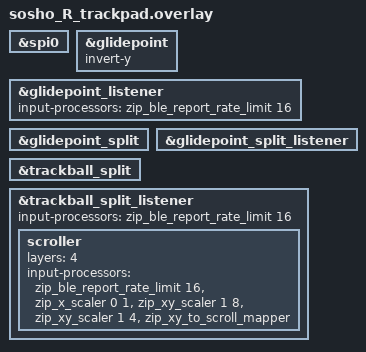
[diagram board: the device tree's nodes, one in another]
#include "sosho_R.dtsi"
#include <input/processors/report_rate_limit.dtsi>

/*
glidepoint_listnerは右手のトラックパッド
glidepoint_split_listenerとtrackball_split_listenerは
左手のトラックパッドとトラックボールの受けです。
ここにinput-processorというオプションをつけると、いろんな動きができます。
代表的なものを書いておきます。

・ポインタの移動を早くしたいとき
&zip_xy_scalerを使います。
分子 分母の順に数字を指定します。2 1なら2倍です。
input-processors = <&zip_xy_scaler 2 1>;

・スクロールを割り当てたいとき
zip_xy_to_scroll_mapperを使います。
ポインティングデバイスの動きをスクロールに変換してくれます。
input-processors = <&zip_xy_to_scroll_mapper>;

このオプションは複数併記することもできます。
input-processors = <&zip_xy_scaler 1 3>,<&zip_xy_to_scroll_mapper>;

詳しい情報はzmkのドキュメントを確認してください。
https://zmk.dev/docs/keymaps/input-processors
*/

&spi0 { status = "okay"; };
&glidepoint {
    status = "okay";
    invert-y;
};
&glidepoint_listener {
    status = "okay";
	/*
	Bluetooth のときだけ、PC へのレポートを 16 ms に 1 回までにまとめる（間引いた分の動きは次のレポートに足す）。
	作る速さが送る速さを上回ると、送りきれないレポートが溜まって遅れが積み上がり、キーまで遅れるため。
	USB では制限しない。数字を小さくすると滑らかになるが、溜まりやすくなる
	*/
	input-processors = <&zip_ble_report_rate_limit 16>;
	//input-processors = <&zip_ble_report_rate_limit 16>, <&zip_xy_scaler 2 1>;
};

&glidepoint_split { status = "okay"; };
&glidepoint_split_listener {
    status = "okay";
};

&trackball_split { status = "okay"; };
&trackball_split_listener {
	status = "okay";
	// レポートの間引きは glidepoint_listener と同じ（L4 のあいだは下の scroller の設定が代わりに使われるので、そちらにも書く）
	input-processors = <&zip_ble_report_rate_limit 16>;
	//input-processors = <&zip_ble_report_rate_limit 16>, <&zip_xy_scaler 1 3>, <&zip_xy_to_scroll_mapper>;

	/*
	scroll レイヤー（L4）が有効なあいだだけ、左のトラックボールを縦スクロールにする。
	L4 は config/sosho.keymap の 0 番キーの長押しで有効になる。
	・先頭の zip_ble_report_rate_limit は送信の間引き（glidepoint_listener の説明を参照）
	・横の動きは捨てる（zip_x_scaler 0 1）。横スクロールもしたいならこれを外す
	・速さは 2 つの zip_xy_scaler の分母の積で決まる（いまは 8 × 4 = 32 カウントで 1 ノッチ）。
	  遅くしたいなら分母を大きくする（1 つあたり 16 以下が ZMK のドキュメントの推奨。足りなければ段を増やす）
	・向きが逆なら、mapper の前に <&zip_xy_transform INPUT_TRANSFORM_Y_INVERT> を足す
	*/
	scroller {
		layers = <4>;
		input-processors = <&zip_ble_report_rate_limit 16>, <&zip_x_scaler 0 1>, <&zip_xy_scaler 1 8>, <&zip_xy_scaler 1 4>, <&zip_xy_to_scroll_mapper>;
	};
};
